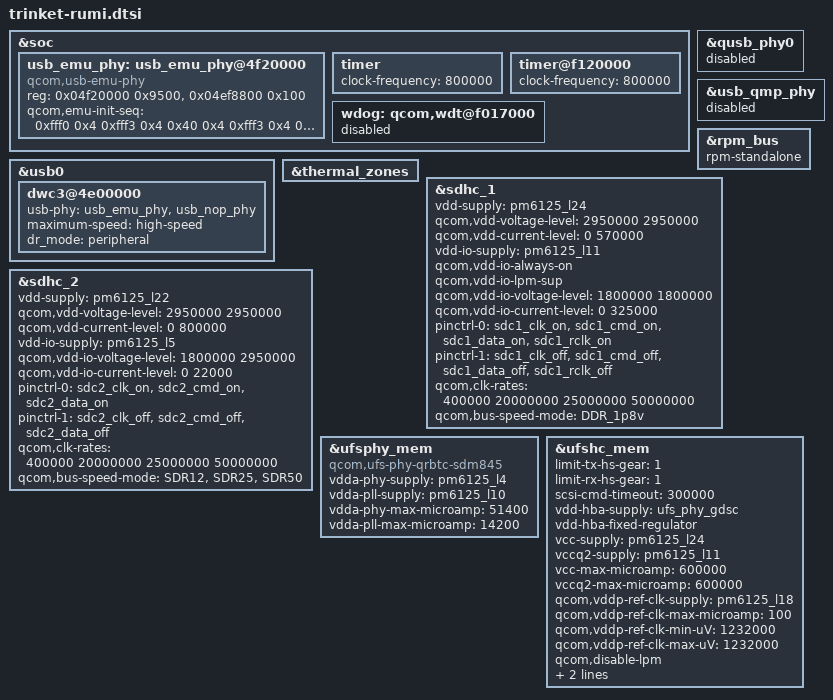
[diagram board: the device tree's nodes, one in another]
/*
 * Copyright (c) 2018-2019, The Linux Foundation. All rights reserved.
 *
 * This program is free software; you can redistribute it and/or modify
 * it under the terms of the GNU General Public License version 2 and
 * only version 2 as published by the Free Software Foundation.
 *
 * This program is distributed in the hope that it will be useful,
 * but WITHOUT ANY WARRANTY; without even the implied warranty of
 * MERCHANTABILITY or FITNESS FOR A PARTICULAR PURPOSE.  See the
 * GNU General Public License for more details.
 */

&soc {
	usb_emu_phy: usb_emu_phy@4f20000 {
			compatible = "qcom,usb-emu-phy";
			reg = <0x04f20000 0x9500>,
				<0x04ef8800 0x100>;
			reg-names = "base", "qcratch_base";

			qcom,emu-init-seq = <0xfff0 0x4
						0xfff3 0x4
						0x40 0x4
						0xfff3 0x4
						0xfff0 0x4
						0x100000 0x20
						0x0 0x20
						0x1a0 0x20
						0x100000 0x3c
						0x0 0x3c
						0x10060 0x3c
						0x0 0x4>;
	};

	timer {
		clock-frequency = <800000>;
	};

	timer@f120000 {
		clock-frequency = <800000>;
	};

	wdog: qcom,wdt@f017000{
		status = "disabled";
	};
};

&usb0 {
	dwc3@4e00000 {
		usb-phy = <&usb_emu_phy>, <&usb_nop_phy>;
		maximum-speed = "high-speed";
		dr_mode = "peripheral";
	};
};

&qusb_phy0 {
	status = "disabled";
};

&usb_qmp_phy {
	status = "disabled";
};

&rpm_bus {
	rpm-standalone;
	/delete-node/ rpm-regulator-smpa3;
	/delete-node/ rpm-regulator-smpa5;
	/delete-node/ rpm-regulator-ldoa1;
	/delete-node/ rpm-regulator-ldoa2;
	/delete-node/ rpm-regulator-ldoa3;
	/delete-node/ rpm-regulator-ldoa4;
	/delete-node/ rpm-regulator-ldoa5;
	/delete-node/ rpm-regulator-ldoa6;
	/delete-node/ rpm-regulator-ldoa7;
	/delete-node/ rpm-regulator-ldoa8;
	/delete-node/ rpm-regulator-ldoa9;
	/delete-node/ rpm-regulator-ldoa10;
	/delete-node/ rpm-regulator-ldoa11;
	/delete-node/ rpm-regulator-ldoa12;
	/delete-node/ rpm-regulator-ldoa13;
	/delete-node/ rpm-regulator-ldoa14;
	/delete-node/ rpm-regulator-ldoa15;
	/delete-node/ rpm-regulator-ldoa16;
	/delete-node/ rpm-regulator-ldoa17;
	/delete-node/ rpm-regulator-ldoa18;
	/delete-node/ rpm-regulator-ldoa19;
	/delete-node/ rpm-regulator-ldoa20;
	/delete-node/ rpm-regulator-ldoa21;
	/delete-node/ rpm-regulator-ldoa22;
	/delete-node/ rpm-regulator-ldoa23;
	/delete-node/ rpm-regulator-ldoa24;
};

&thermal_zones {
	/delete-node/ aoss0-lowf;
	/delete-node/ cdsp-lowf;
	/delete-node/ wlan-lowf;
	/delete-node/ camera-lowf;
	/delete-node/ video-lowf;
	/delete-node/ cpu-1-0-lowf;
	/delete-node/ cpuss-0-lowf;
	/delete-node/ mdm-core-lowf;
	/delete-node/ display-lowf;
	/delete-node/ gpu-lowf;
};

#include "trinket-stub-regulator.dtsi"

&sdhc_1 {
	vdd-supply = <&pm6125_l24>;
	qcom,vdd-voltage-level = <2950000 2950000>;
	qcom,vdd-current-level = <0 570000>;

	vdd-io-supply = <&pm6125_l11>;
	qcom,vdd-io-always-on;
	qcom,vdd-io-lpm-sup;
	qcom,vdd-io-voltage-level = <1800000 1800000>;
	qcom,vdd-io-current-level = <0 325000>;

	pinctrl-names = "active", "sleep";
	pinctrl-0 = <&sdc1_clk_on &sdc1_cmd_on &sdc1_data_on
					&sdc1_rclk_on>;
	pinctrl-1 = <&sdc1_clk_off &sdc1_cmd_off &sdc1_data_off
					&sdc1_rclk_off>;

	qcom,clk-rates = <400000 20000000 25000000 50000000>;
	qcom,bus-speed-mode = "DDR_1p8v";

	/delete-property/qcom,devfreq,freq-table;

	status = "ok";
};

&sdhc_2 {
	vdd-supply = <&pm6125_l22>;
	qcom,vdd-voltage-level = <2950000 2950000>;
	qcom,vdd-current-level = <0 800000>;

	vdd-io-supply = <&pm6125_l5>;
	qcom,vdd-io-voltage-level = <1800000 2950000>;
	qcom,vdd-io-current-level = <0 22000>;

	pinctrl-names = "active", "sleep";
	pinctrl-0 = <&sdc2_clk_on  &sdc2_cmd_on &sdc2_data_on>;
	pinctrl-1 = <&sdc2_clk_off &sdc2_cmd_off &sdc2_data_off>;

	qcom,clk-rates = <400000 20000000 25000000 50000000>;
	qcom,bus-speed-mode = "SDR12", "SDR25", "SDR50";

	/delete-property/qcom,devfreq,freq-table;

	status = "ok";
};

&ufsphy_mem {
	compatible = "qcom,ufs-phy-qrbtc-sdm845";

	vdda-phy-supply = <&pm6125_l4>; /* 0.9v */
	vdda-pll-supply = <&pm6125_l10>; /* 1.8v */
	vdda-phy-max-microamp = <51400>;
	vdda-pll-max-microamp = <14200>;

	status = "ok";
};

&ufshc_mem {
	limit-tx-hs-gear = <1>;
	limit-rx-hs-gear = <1>;
	scsi-cmd-timeout = <300000>;

	vdd-hba-supply = <&ufs_phy_gdsc>;
	vdd-hba-fixed-regulator;
	vcc-supply = <&pm6125_l24>;
	vccq2-supply = <&pm6125_l11>;
	vcc-max-microamp = <600000>;
	vccq2-max-microamp = <600000>;

	qcom,vddp-ref-clk-supply = <&pm6125_l18>;
	qcom,vddp-ref-clk-max-microamp = <100>;
	qcom,vddp-ref-clk-min-uV = <1232000>;
	qcom,vddp-ref-clk-max-uV = <1232000>;

	qcom,disable-lpm;
	rpm-level = <0>;
	spm-level = <0>;
	status = "ok";
};
